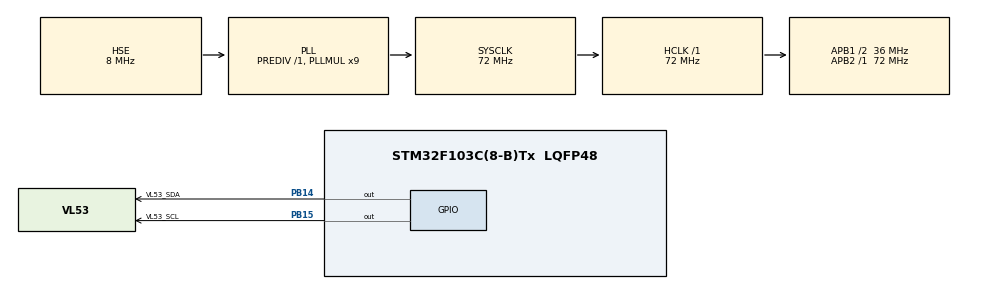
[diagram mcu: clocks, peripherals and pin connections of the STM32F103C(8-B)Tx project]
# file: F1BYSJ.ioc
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Mcu.Family=STM32F1
Mcu.Name=STM32F103C(8-B)Tx
Mcu.Package=LQFP48
NVIC.PriorityGroup=NVIC_PRIORITYGROUP_4
NVIC.TIM1_UP_IRQn=true\:0\:0\:false\:false\:true\:false\:true
NVIC.TimeBase=TIM1_UP_IRQn
NVIC.TimeBaseIP=TIM1
PA13.Mode=Serial_Wire
PA13.Signal=SYS_JTMS-SWDIO
PA14.Mode=Serial_Wire
PA14.Signal=SYS_JTCK-SWCLK
PB14.GPIO_Label=VL53_SDA
PB14.GPIO_ModeDefaultOutputPP=GPIO_MODE_OUTPUT_OD
PB14.GPIO_PuPd=GPIO_PULLUP
PB14.GPIO_Speed=GPIO_SPEED_FREQ_LOW
PB14.Signal=GPIO_Output
PB15.GPIO_Label=VL53_SCL
PB15.GPIO_ModeDefaultOutputPP=GPIO_MODE_OUTPUT_OD
PB15.GPIO_PuPd=GPIO_PULLUP
PB15.Signal=GPIO_Output
PD0-OSC_IN.Mode=HSE-External-Oscillator
PD0-OSC_IN.Signal=RCC_OSC_IN
PD1-OSC_OUT.Mode=HSE-External-Oscillator
PD1-OSC_OUT.Signal=RCC_OSC_OUT
ProjectManager.HeapSize=0x200
ProjectManager.StackSize=0x400
ProjectManager.TargetToolchain=MDK-ARM V5
RCC.ADCPresc=RCC_ADCPCLK2_DIV6
RCC.AHBFreq_Value=72000000
RCC.APB1CLKDivider=RCC_HCLK_DIV2
RCC.APB1Freq_Value=36000000
RCC.APB1TimFreq_Value=72000000
RCC.APB2Freq_Value=72000000
RCC.APB2TimFreq_Value=72000000
RCC.HCLKFreq_Value=72000000
RCC.PLLMUL=RCC_PLL_MUL9
RCC.PLLSourceVirtual=RCC_PLLSOURCE_HSE
RCC.SYSCLKFreq_VALUE=72000000
RCC.SYSCLKSource=RCC_SYSCLKSOURCE_PLLCLK
RCC.USBFreq_Value=48000000
RCC.USBPrescaler=RCC_USBCLKSOURCE_PLL_DIV1_5
VP_SYS_VS_tim1.Mode=TIM1
board=custom

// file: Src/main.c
/* USER CODE BEGIN Header */
/**
  ******************************************************************************
  * @file           : main.c
  * @brief          : Main program body
  ******************************************************************************
  * @attention
  *
  * <h2><center>&copy; Copyright (c) 2020 STMicroelectronics.
  * All rights reserved.</center></h2>
  *
  * This software component is licensed by ST under Ultimate Liberty license
  * SLA0044, the "License"; You may not use this file except in compliance with
  * the License. You may obtain a copy of the License at:
  *                             www.st.com/SLA0044
  *
  ******************************************************************************
  */
/* USER CODE END Header */

#include "main.h"
#include "gpio.h"

/* USER CODE BEGIN Includes */

#pragma import(__use_no_semihosting)
#include "stdio.h"
#include "vl53l1.h"
/* USER CODE END Includes */

/* USER CODE BEGIN PV */
uint8_t tmpconsole[512];
uint16_t consoleindex=0;
/* Private variables ---------------------------------------------------------*/

/* USER CODE END PV */

void SystemClock_Config(void);
/* USER CODE BEGIN PFP */
/* Private function prototypes -----------------------------------------------*/

/* USER CODE END PFP */

int main(void)
{

  /* MCU Configuration--------------------------------------------------------*/

  /* Reset of all peripherals, Initializes the Flash interface and the Systick. */
  HAL_Init();

  /* Configure the system clock */
  SystemClock_Config();

  /* Initialize all configured peripherals */
  MX_GPIO_Init();
  /* USER CODE BEGIN 2 */
  VL53L1Init(&VL53);
  VL53InitParam(&VL53,2);
  /* USER CODE END 2 */

  /* Infinite loop */
  while (1)
  {

    /* USER CODE BEGIN 3 */
    getDistance(&VL53);
  }
  /* USER CODE END 3 */
}

void SystemClock_Config(void)
{
  RCC_OscInitTypeDef RCC_OscInitStruct = {0};
  RCC_ClkInitTypeDef RCC_ClkInitStruct = {0};

  /** Initializes the CPU, AHB and APB busses clocks
  */
  RCC_OscInitStruct.OscillatorType = RCC_OSCILLATORTYPE_HSE;
  RCC_OscInitStruct.HSEState = RCC_HSE_ON;
  RCC_OscInitStruct.HSEPredivValue = RCC_HSE_PREDIV_DIV1;
  RCC_OscInitStruct.HSIState = RCC_HSI_ON;
  RCC_OscInitStruct.PLL.PLLState = RCC_PLL_ON;
  RCC_OscInitStruct.PLL.PLLSource = RCC_PLLSOURCE_HSE;
  RCC_OscInitStruct.PLL.PLLMUL = RCC_PLL_MUL9;
  if (HAL_RCC_OscConfig(&RCC_OscInitStruct) != HAL_OK)
  {
    Error_Handler();
  }
  /** Initializes the CPU, AHB and APB busses clocks
  */
  RCC_ClkInitStruct.ClockType = RCC_CLOCKTYPE_HCLK|RCC_CLOCKTYPE_SYSCLK
                              |RCC_CLOCKTYPE_PCLK1|RCC_CLOCKTYPE_PCLK2;
  RCC_ClkInitStruct.SYSCLKSource = RCC_SYSCLKSOURCE_PLLCLK;
  RCC_ClkInitStruct.AHBCLKDivider = RCC_SYSCLK_DIV1;
  RCC_ClkInitStruct.APB1CLKDivider = RCC_HCLK_DIV2;
  RCC_ClkInitStruct.APB2CLKDivider = RCC_HCLK_DIV1;

  if (HAL_RCC_ClockConfig(&RCC_ClkInitStruct, FLASH_LATENCY_2) != HAL_OK)
  {
    Error_Handler();
  }
}

/* USER CODE BEGIN 4 */
struct __FILE
{
int handle;
};
FILE __stdout;
void _sys_exit(int x)
{
    x = x;
}
int fputc(int ch, FILE *f)
{
    tmpconsole[consoleindex++]=ch;
    if(consoleindex>=sizeof(tmpconsole))consoleindex=0;
    return ch;
}
/* USER CODE END 4 */

 /**
  * @brief  Period elapsed callback in non blocking mode
  * @note   This function is called  when TIM1 interrupt took place, inside
  * HAL_TIM_IRQHandler(). It makes a direct call to HAL_IncTick() to increment
  * a global variable "uwTick" used as application time base.
  * @param  htim : TIM handle
  * @retval None
  */
void HAL_TIM_PeriodElapsedCallback(TIM_HandleTypeDef *htim)
{
  if (htim->Instance == TIM1) {
    HAL_IncTick();
  }
}

void Error_Handler(void)
{
  while(1)
  {
  }
}

/************************ (C) COPYRIGHT STMicroelectronics *****END OF FILE****/
